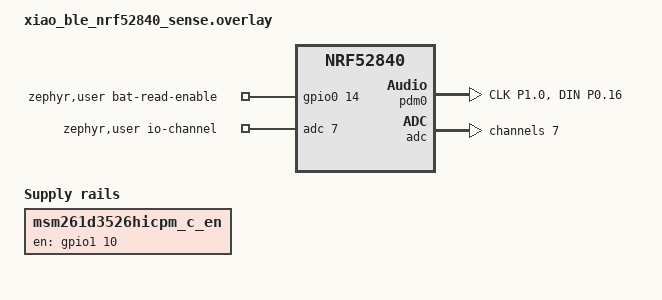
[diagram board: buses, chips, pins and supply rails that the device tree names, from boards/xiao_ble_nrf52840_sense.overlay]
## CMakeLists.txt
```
# SPDX-License-Identifier: Apache-2.0

cmake_minimum_required(VERSION 3.20.0)

set(PM_STATIC_YML_FILE ${CMAKE_CURRENT_SOURCE_DIR}/pm_static.yml)

find_package(Zephyr REQUIRED HINTS $ENV{ZEPHYR_BASE})
project(nordic_main)

target_sources(app PRIVATE
    src/main.c
    src/audio_capture.c
    src/adpcm.c
)
```

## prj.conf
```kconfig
# Zephyr Kernel Configuration for XIAO nRF52840 Sense - nordic-main (Handy BLE)

CONFIG_MAIN_STACK_SIZE=4096

# Heap (BLE stack + MCUmgr + audio needs memory)
CONFIG_HEAP_MEM_POOL_SIZE=65536
CONFIG_SYSTEM_WORKQUEUE_STACK_SIZE=4096

# Logging and console (USB CDC ACM on XIAO nRF52840)
CONFIG_LOG=y
CONFIG_LOG_MODE_DEFERRED=n
CONFIG_CONSOLE=y
CONFIG_UART_CONSOLE=y
CONFIG_PRINTK=y
CONFIG_CBPRINTF_FP_SUPPORT=y

# USB CDC ACM console
CONFIG_USB_CDC_ACM=y

# Peripherals
CONFIG_GPIO=y
CONFIG_PINCTRL=y

# Audio (PDM microphone)
CONFIG_AUDIO=y
CONFIG_AUDIO_DMIC=y

# Bluetooth Low Energy
CONFIG_BT=y
CONFIG_BT_PERIPHERAL=y
CONFIG_BT_BROADCASTER=y
CONFIG_BT_MAX_CONN=2
CONFIG_BT_SMP=n
CONFIG_BT_GATT_DYNAMIC_DB=y
CONFIG_BT_DEVICE_NAME="HarnessNode"
CONFIG_BT_DEVICE_NAME_DYNAMIC=y
CONFIG_BT_DEVICE_NAME_MAX=20
CONFIG_BT_GATT_CLIENT=y

# BLE MTU (OTA transfer efficiency + audio throughput)
CONFIG_BT_L2CAP_TX_MTU=244
CONFIG_BT_BUF_ACL_RX_SIZE=251
CONFIG_BT_BUF_ACL_TX_SIZE=251
CONFIG_BT_CTLR_DATA_LENGTH_MAX=251
CONFIG_BT_L2CAP_TX_BUF_COUNT=8
CONFIG_BT_ATT_TX_COUNT=8
CONFIG_BT_CONN_TX_MAX=8

# GAP PPCP (Android may apply these after discovery).
# Zephyr default timeout=42 (420 ms) is too short and drops the link.
CONFIG_BT_PERIPHERAL_PREF_MIN_INT=24
CONFIG_BT_PERIPHERAL_PREF_MAX_INT=40
CONFIG_BT_PERIPHERAL_PREF_LATENCY=0
CONFIG_BT_PERIPHERAL_PREF_TIMEOUT=800

# MCUmgr (SMP server for BLE OTA)
CONFIG_MCUMGR=y
CONFIG_MCUMGR_TRANSPORT_BT=y
CONFIG_MCUMGR_GRP_IMG=y
CONFIG_MCUMGR_GRP_IMG_VERBOSE_ERR=y
CONFIG_MCUBOOT_IMGTOOL_SIGN_VERSION="0.0.100+0"
CONFIG_MCUMGR_GRP_OS=y

# MCUmgr dependencies
CONFIG_IMG_MANAGER=y
CONFIG_MCUBOOT_IMG_MANAGER=y
CONFIG_FLASH=y
CONFIG_FLASH_MAP=y
CONFIG_STREAM_FLASH=y
CONFIG_NET_BUF=y
CONFIG_ZCBOR=y

# Settings persistence (image confirm state survives reboot)
CONFIG_SETTINGS=y
CONFIG_SETTINGS_FCB=y
CONFIG_FCB=y

# Watchdog timer
CONFIG_WATCHDOG=y

# SYSTEMOFF after 3 min unconnected (double-tap IMU INT1 wakes)
CONFIG_POWEROFF=y

# Hardware info (read reset cause)
CONFIG_HWINFO=y

# I2C + IMU（LSM6DS3TR-C）
CONFIG_I2C=y
CONFIG_SENSOR=y
CONFIG_LSM6DSL=y
CONFIG_LSM6DSL_TRIGGER_GLOBAL_THREAD=y

# Battery monitoring
CONFIG_ADC=y
CONFIG_BT_BAS=y
CONFIG_NRFX_POWER=y
```

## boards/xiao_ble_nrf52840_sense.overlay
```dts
/*
 * Device Tree Overlay for Seeed Studio XIAO nRF52840 Sense
 * nordic-main: PDM microphone + IMU + flash partitions
 *
 * Partition DTS ID assignment (sorted by address):
 *   0x00000 sd_partition        → 0  (board DTS)
 *   0x27000 code_partition      → 1  (board DTS)
 *   0x2f000 mcuboot_pad_part   → 2  = PM_MCUBOOT_PAD_ID(2)
 *   0x33000 slot0_partition     → 3  = PM_MCUBOOT_PRIMARY_ID(3) ← MCUmgr slot0
 *   0x33200 app_part            → 4  = PM_APP_ID(4)
 *   0x34000 primary_app_part    → 5  = PM_MCUBOOT_PRIMARY_APP(5)
 *   0x85000 slot1_partition     → 6  = PM_MCUBOOT_SECONDARY_ID(6) ← MCUmgr slot1
 *   0xec000 storage_partition   → 7  = PM_SETTINGS_STORAGE_ID(7) (board DTS)
 *   0xf4000 boot_partition      → 8  = PM_ADAFRUIT_BOOT_ID(8)    (board DTS)
 */

/ {
    aliases {
        dmic0 = &pdm0;
        imu0 = &lsm6ds3tr_c;
    };

    /* Enable microphone power at boot (P1.10 — not enabled by board DTS by default) */
    msm261d3526hicpm_c_en: msm261d3526hicpm-c-en {
        compatible = "regulator-fixed-sync", "regulator-fixed";
        enable-gpios = <&gpio1 10 (NRF_GPIO_DRIVE_S0H1 | GPIO_ACTIVE_HIGH)>;
        regulator-name = "MSM261D3526HICPM-C-EN";
    };
};

&pinctrl {
    pdm0_default_alt: pdm0_default_alt {
        group1 {
            psels = <NRF_PSEL(PDM_CLK, 1, 0)>,   /* P1.00 */
                    <NRF_PSEL(PDM_DIN, 0, 16)>;   /* P0.16 */
        };
    };

    pdm0_sleep_alt: pdm0_sleep_alt {
        group1 {
            psels = <NRF_PSEL(PDM_CLK, 1, 0)>,
                    <NRF_PSEL(PDM_DIN, 0, 16)>;
            low-power-enable;
        };
    };
};

&pdm0 {
    status = "okay";
    pinctrl-0 = <&pdm0_default_alt>;
    pinctrl-1 = <&pdm0_sleep_alt>;
    pinctrl-names = "default", "sleep";
};

/ {
    zephyr,user {
        /* P0.31 = AIN7 — actual battery voltage ADC input (1/2 divider) */
        io-channels = <&adc 7>;
        /* P0.14 = battery measurement enable (set HIGH before reading) */
        bat-read-enable-gpios = <&gpio0 14 GPIO_ACTIVE_HIGH>;
    };
};

&adc {
    status = "okay";
    #address-cells = <1>;
    #size-cells = <0>;

    channel@7 {
        reg = <7>;
        zephyr,gain = "ADC_GAIN_1_6";
        zephyr,reference = "ADC_REF_INTERNAL";
        zephyr,acquisition-time = <ADC_ACQ_TIME_DEFAULT>;
        zephyr,input-positive = <NRF_SAADC_AIN7>; /* P0.31 */
        zephyr,resolution = <12>;
        zephyr,oversampling = <4>;
    };
};

&flash0 {
    partitions {
        /* ID 2 — matches PM_MCUBOOT_PAD_ID = 2 */
        mcuboot_pad_part: partition@2f000 {
            label = "mcuboot-pad";
            reg = <0x2f000 0x200>;
        };

        /* ID 3 — matches PM_MCUBOOT_PRIMARY_ID = 3 → used by MCUmgr as slot 0 */
        slot0_partition: partition@33000 {
            label = "image-0";
            reg = <0x33000 0x52000>;
        };

        /* ID 4 — matches PM_APP_ID = 4 */
        app_part: partition@33200 {
            label = "app";
            reg = <0x33200 0x51e00>;
        };

        /* ID 5 — matches PM_MCUBOOT_PRIMARY_APP_ID = 5 */
        primary_app_part: partition@34000 {
            label = "mcuboot-primary-app";
            reg = <0x34000 0x51000>;
        };

        /* ID 6 — matches PM_MCUBOOT_SECONDARY_ID = 6 → used by MCUmgr as slot 1 */
        slot1_partition: partition@85000 {
            label = "image-1";
            reg = <0x85000 0x52000>;
        };
    };
};
```

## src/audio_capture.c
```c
/*
 * Audio Capture for Voice Bridge BLE
 * PDM Microphone via Zephyr DMIC API on nRF52840
 *
 * Ported from nrf54l15/src/audio_capture.c:
 *   - DT alias: dmic20 → dmic0
 *   - Fallback node: pdm20 → pdm0
 *   - PDM CLK: P1.12 → P1.00
 *   - PDM DIN: P1.13 → P0.16  (configured in board overlay)
 */

#include <zephyr/kernel.h>
#include <zephyr/device.h>
#include <zephyr/audio/dmic.h>
#include <zephyr/logging/log.h>

#include "audio_capture.h"

LOG_MODULE_REGISTER(audio_capture, LOG_LEVEL_INF);

/* ============================================================================
 * Configuration
 * ============================================================================ */

#define SAMPLE_RATE         16000
#define SAMPLE_BITS         16
#define CHANNELS            1
#define BYTES_PER_SAMPLE    sizeof(int16_t)

/* 20ms frame = 320 samples = 640 bytes */
#define FRAME_MS            20
#define FRAME_SAMPLES       (SAMPLE_RATE * FRAME_MS / 1000)
#define FRAME_BYTES         (FRAME_SAMPLES * BYTES_PER_SAMPLE * CHANNELS)

/*
 * DMIC driver slab. Keep well above one BLE backpressure stall so the PDM
 * DMA path can continue while the sender thread drains Notify slots.
 * 12 × 20 ms = 240 ms of hardware buffering.
 */
#define BLOCK_COUNT         12
K_MEM_SLAB_DEFINE_STATIC(pdm_mem_slab, FRAME_BYTES, BLOCK_COUNT, 4);

/* ============================================================================
 * Global Variables
 * ============================================================================ */

static const struct device *dmic_dev;
static bool dmic_configured = false;
static bool dmic_started = false;

/* Current audio buffer from dmic_read */
static void *current_block = NULL;
static bool pdm_hw_running = false;

/* ============================================================================
 * Public API
 * ============================================================================ */

int audio_capture_init(void)
{
    if (dmic_configured) {
        return 0;
    }

#ifdef DT_N_ALIAS_dmic0
    dmic_dev = DEVICE_DT_GET(DT_ALIAS(dmic0));
#else
    dmic_dev = DEVICE_DT_GET(DT_NODELABEL(pdm0));
#endif
    if (!device_is_ready(dmic_dev)) {
        LOG_ERR("DMIC device not ready: %s", dmic_dev->name);
        printk("!!! DMIC device not ready: %s\n", dmic_dev->name);
        return -ENODEV;
    }

    struct pcm_stream_cfg stream = {
        .pcm_width = SAMPLE_BITS,
        .pcm_rate  = SAMPLE_RATE,
        .block_size = FRAME_BYTES,
        .mem_slab  = &pdm_mem_slab,
    };

    struct dmic_cfg cfg = {
        .io = {
            .min_pdm_clk_freq = 1000000,
            .max_pdm_clk_freq = 3500000,
            .min_pdm_clk_dc   = 40,
            .max_pdm_clk_dc   = 60,
        },
        .streams = &stream,
        .channel = {
            .req_num_streams = 1,
            .req_num_chan = CHANNELS,
            .req_chan_map_lo = dmic_build_channel_map(0, 0, PDM_CHAN_RIGHT),
        },
    };

    int ret = dmic_configure(dmic_dev, &cfg);
    if (ret < 0) {
        LOG_ERR("DMIC configure failed: %d", ret);
        printk("!!! DMIC configure failed: %d\n", ret);
        return ret;
    }

    dmic_configured = true;

    LOG_INF("Audio capture initialized: %d Hz, %d-bit, %d ch, %d ms frames",
            SAMPLE_RATE, SAMPLE_BITS, CHANNELS, FRAME_MS);
    printk("Audio init OK: %d Hz, %d samples/frame\n", SAMPLE_RATE, FRAME_SAMPLES);
    return 0;
}

int audio_capture_start(void)
{
    if (!dmic_configured) {
        return -EIO;
    }

    if (dmic_started) {
        return 0;
    }

    int ret = dmic_trigger(dmic_dev, DMIC_TRIGGER_START);
    if (ret < 0) {
        LOG_ERR("DMIC start failed: %d", ret);
        printk("!!! DMIC start failed: %d\n", ret);
        return ret;
    }
    pdm_hw_running = true;

    /*
     * Discard frames until the PDM CIC filter's DC offset settles.
     * Fresh start produces a large negative offset (~-30000) that decays
     * ~7.5% per 20ms frame, converging to the mic's bias (~-8).
     * Discard up to 80 frames (1.6s), stopping early when |DC| < 200.
     */
    for (int i = 0; i < 80; i++) {
        void *blk = NULL;
        uint32_t sz;
        if (dmic_read(dmic_dev, 0, &blk, &sz, 100) < 0 || blk == NULL) {
            break;
        }
        int16_t *s = (int16_t *)blk;
        int32_t dc = 0;
        uint32_t n = sz / sizeof(int16_t);
        for (uint32_t j = 0; j < n; j++) {
            dc += s[j];
        }
        dc /= (int32_t)n;
        k_mem_slab_free(&pdm_mem_slab, blk);
        if (dc > -200 && dc < 200) {
            printk("PDM settled after %d frames (DC=%d)\n", i + 1, (int)dc);
            break;
        }
    }

    dmic_started = true;
    LOG_INF("Audio capture started");
    printk("Audio started\n");
    return 0;
}

int audio_capture_stop(void)
{
    if (!dmic_started) {
        return 0;
    }

    int ret = dmic_trigger(dmic_dev, DMIC_TRIGGER_STOP);
    if (ret < 0) {
        LOG_ERR("DMIC stop failed: %d", ret);
        return ret;
    }
    pdm_hw_running = false;

    if (current_block) {
        k_mem_slab_free(&pdm_mem_slab, current_block);
        current_block = NULL;
    }

    dmic_started = false;
    LOG_INF("Audio capture stopped");
    return 0;
}

int audio_capture_get_data(int16_t **buffer, size_t *size)
{
    if (!dmic_started) {
        return -EAGAIN;
    }

    if (current_block) {
        k_mem_slab_free(&pdm_mem_slab, current_block);
        current_block = NULL;
    }

    uint32_t read_size;
    int ret = dmic_read(dmic_dev, 0, &current_block, &read_size, 200);
    if (ret < 0) {
        LOG_WRN("DMIC read failed: %d", ret);
        return ret;
    }

    if (buffer) {
        *buffer = (int16_t *)current_block;
    }
    if (size) {
        *size = read_size;
    }

    return 0;
}

size_t audio_capture_get_frame_size(void)
{
    return FRAME_BYTES;
}

uint32_t audio_capture_get_sample_rate(void)
{
    return SAMPLE_RATE;
}
```

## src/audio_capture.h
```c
/*
 * Audio Capture Module for Voice Bridge BLE
 * PDM Microphone interface using Zephyr Audio Subsystem
 */

#ifndef AUDIO_CAPTURE_H
#define AUDIO_CAPTURE_H

#include <stdint.h>
#include <stddef.h>

#ifdef __cplusplus
extern "C" {
#endif

/**
 * Initialize audio capture from PDM microphone
 * 
 * @return 0 on success, negative errno on failure
 */
int audio_capture_init(void);

/**
 * Start audio capture
 * 
 * @return 0 on success, negative errno on failure
 */
int audio_capture_start(void);

/**
 * Stop audio capture
 * 
 * @return 0 on success, negative errno on failure
 */
int audio_capture_stop(void);

/**
 * Get audio data from capture buffer
 * 
 * @param buffer Pointer to receive buffer pointer
 * @param size Pointer to receive data size
 * @return 0 on success, negative errno on failure
 */
int audio_capture_get_data(int16_t **buffer, size_t *size);

/**
 * Get frame size in bytes
 *
 * @return Frame size
 */
size_t audio_capture_get_frame_size(void);

/**
 * Get sample rate
 * 
 * @return Sample rate in Hz
 */
uint32_t audio_capture_get_sample_rate(void);

#ifdef __cplusplus
}
#endif

#endif /* AUDIO_CAPTURE_H */
```
